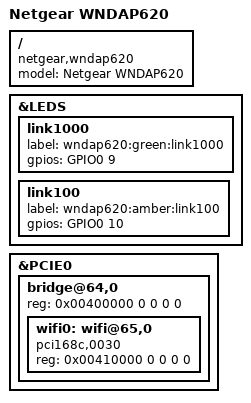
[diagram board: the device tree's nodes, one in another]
/*
 * Device Tree Source for Netgear WNDAP620
 *
 * This file is licensed under the terms of the GNU General Public
 * License version 2.  This program is licensed "as is" without
 * any warranty of any kind, whether express or implied.
 */

/dts-v1/;

#include "netgear-wndap6x0.dtsi"

/ {
	model = "Netgear WNDAP620";
	compatible = "netgear,wndap620", "apm,bluestone";
};

&LEDS {
	link1000 {
		label = "wndap620:green:link1000";
		gpios = <&GPIO0 9 GPIO_ACTIVE_HIGH>;
	};

	link100 {
		label = "wndap620:amber:link100";
		gpios = <&GPIO0 10 GPIO_ACTIVE_HIGH>;
	};
};

&PCIE0 {
	/*
	 * relevant lspci topology:
	 *
	 *	-+-[0000:40]---00.0-[41-7f]----00.0
	 */

	bridge@64,0 {
		reg = <0x00400000 0 0 0 0>;
		#address-cells = <3>;
		#size-cells = <2>;
		ranges;

		wifi0: wifi@65,0 {
			/* Atheros AR9380 5GHz */
			compatible = "pci168c,0030";
			reg = <0x00410000 0 0 0 0>;
		};
	};
};
